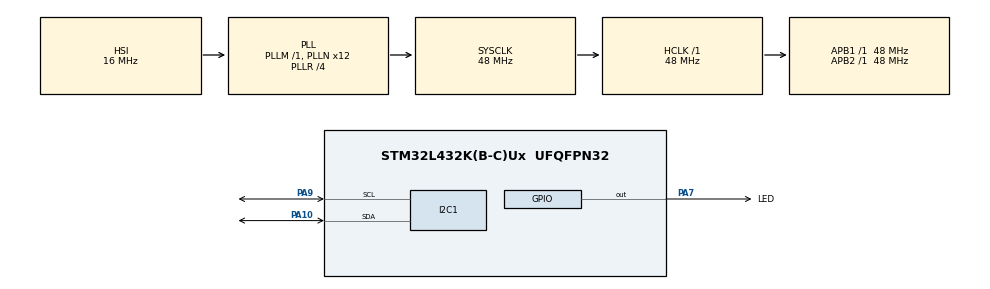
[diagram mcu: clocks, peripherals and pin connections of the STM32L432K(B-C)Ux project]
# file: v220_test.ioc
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I2C1.Timing=0x10805D88
Mcu.Family=STM32L4
Mcu.Name=STM32L432K(B-C)Ux
Mcu.Package=UFQFPN32
NVIC.PriorityGroup=NVIC_PRIORITYGROUP_4
PA10.Mode=I2C
PA10.Signal=I2C1_SDA
PA13\ (JTMS-SWDIO).Mode=Serial_Wire
PA13\ (JTMS-SWDIO).Signal=SYS_JTMS-SWDIO
PA14\ (JTCK-SWCLK).Mode=Serial_Wire
PA14\ (JTCK-SWCLK).Signal=SYS_JTCK-SWCLK
PA7.GPIO_Label=LED
PA7.Signal=GPIO_Output
PA9.Mode=I2C
PA9.Signal=I2C1_SCL
ProjectManager.HeapSize=0x400
ProjectManager.StackSize=0x800
ProjectManager.TargetToolchain=STM32CubeIDE
RCC.ADCFreq_Value=64000000
RCC.AHBFreq_Value=48000000
RCC.APB1Freq_Value=48000000
RCC.APB1TimFreq_Value=48000000
RCC.APB2Freq_Value=48000000
RCC.APB2TimFreq_Value=48000000
RCC.CortexFreq_Value=48000000
RCC.HCLKFreq_Value=48000000
RCC.HSE_VALUE=8000000
RCC.HSI48_VALUE=48000000
RCC.HSI_VALUE=16000000
RCC.LSE_VALUE=32768
RCC.MSI_VALUE=4000000
RCC.PLLN=12
RCC.PLLR=RCC_PLLR_DIV4
RCC.PLLSourceVirtual=RCC_PLLSOURCE_HSI
RCC.SYSCLKFreq_VALUE=48000000
RCC.SYSCLKSource=RCC_SYSCLKSOURCE_PLLCLK
RCC.USBFreq_Value=64000000
RCC.VCOOutputFreq_Value=192000000
board=custom

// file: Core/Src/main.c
/* USER CODE BEGIN Header */
/**
  ******************************************************************************
  * @file           : main.c
  * @brief          : Main program body
  ******************************************************************************
  * @attention
  *
  * <h2><center>&copy; Copyright (c) 2021 STMicroelectronics.
  * All rights reserved.</center></h2>
  *
  * This software component is licensed by ST under BSD 3-Clause license,
  * the "License"; You may not use this file except in compliance with the
  * License. You may obtain a copy of the License at:
  *                        opensource.org/licenses/BSD-3-Clause
  *
  ******************************************************************************
  */
/* USER CODE END Header */
#include "main.h"

/* USER CODE BEGIN Includes */
#include "stdbool.h"
#include "stdlib.h"
#include "stdio.h"
#include "inttypes.h"
#include "string.h"
#include "math.h"
#include "INA3221.h"
/* USER CODE END Includes */

/* USER CODE BEGIN PTD */

INA3221 ina;
uint32_t speed_tick_sec=0,tick=0,tick_sec=0;
float gerilim[3];

float akim[3];
int MID;

/* USER CODE END PTD */

I2C_HandleTypeDef hi2c1;

void SystemClock_Config(void);
static void MX_GPIO_Init(void);
static void MX_I2C1_Init(void);

int main(void)
{

  /* MCU Configuration--------------------------------------------------------*/

  /* Reset of all peripherals, Initializes the Flash interface and the Systick. */
  HAL_Init();

  /* Configure the system clock */
  SystemClock_Config();

  /* Initialize all configured peripherals */
  MX_GPIO_Init();
  MX_I2C1_Init();
  /* USER CODE BEGIN 2 */

  speed_tick_sec=tick=tick_sec=HAL_GetTick();
  INA3221_init(&hi2c1);
  ina.i2caddr=INA3221_ADDRESS;
  ina.shuntresistor[0]=SHUNT_10m;
  ina.shuntresistor[1]=SHUNT_10m;
  ina.shuntresistor[2]=SHUNT_10m;
  ina.enable[0]=1;
  ina.enable[1]=1;
  ina.enable[2]=1;
  ina.acdc[0]=AC;
  ina.acdc[1]=DC;
  ina.acdc[2]=DC;

  INA3221_begin(&ina);

  MID = INA3221_getManufID(&ina);
  /* USER CODE END 2 */

  /* Infinite loop */
  /* USER CODE BEGIN WHILE */
  while (1)
  {
	  tick=HAL_GetTick();

	  if(tick>=speed_tick_sec && (uint32_t)(tick-speed_tick_sec)>=3000)
	  {

		  speed_tick_sec=tick;
	  }
	  if(tick>=tick_sec && (uint32_t)(tick-tick_sec)>=500)
	  {
		  for(int i=0;i<3;i++)
		  {
		  	if(ina.enable[i]==1){

		  		if(ina.acdc[i]==AC){
		  			gerilim[i]=INA3221_getBusVoltage_V(&ina,i+1)*28.87824;
		  			gerilim[i]/=sqrt(2);
		  			gerilim[i]=(gerilim[i]==0)?0:(gerilim[i]+1);
		  		}
		  		else{
		  			gerilim[i]=INA3221_getBusVoltage_V(&ina,i+1)*28.87824;
		  			gerilim[i]=(gerilim[i]==0)?0:(gerilim[i]-1);
		  		}
		  		akim[i]=INA3221_getCurrent_mA(&ina,i+1);

		  	}
		  }
	  tick_sec=tick;
	  }

    /* USER CODE END WHILE */

  }
}

void SystemClock_Config(void)
{
  RCC_OscInitTypeDef RCC_OscInitStruct = {0};
  RCC_ClkInitTypeDef RCC_ClkInitStruct = {0};

  /** Configure the main internal regulator output voltage
  */
  if (HAL_PWREx_ControlVoltageScaling(PWR_REGULATOR_VOLTAGE_SCALE1) != HAL_OK)
  {
    Error_Handler();
  }

  /** Initializes the RCC Oscillators according to the specified parameters
  * in the RCC_OscInitTypeDef structure.
  */
  RCC_OscInitStruct.OscillatorType = RCC_OSCILLATORTYPE_HSI;
  RCC_OscInitStruct.HSIState = RCC_HSI_ON;
  RCC_OscInitStruct.HSICalibrationValue = RCC_HSICALIBRATION_DEFAULT;
  RCC_OscInitStruct.PLL.PLLState = RCC_PLL_ON;
  RCC_OscInitStruct.PLL.PLLSource = RCC_PLLSOURCE_HSI;
  RCC_OscInitStruct.PLL.PLLM = 1;
  RCC_OscInitStruct.PLL.PLLN = 12;
  RCC_OscInitStruct.PLL.PLLP = RCC_PLLP_DIV7;
  RCC_OscInitStruct.PLL.PLLQ = RCC_PLLQ_DIV2;
  RCC_OscInitStruct.PLL.PLLR = RCC_PLLR_DIV4;
  if (HAL_RCC_OscConfig(&RCC_OscInitStruct) != HAL_OK)
  {
    Error_Handler();
  }

  /** Initializes the CPU, AHB and APB buses clocks
  */
  RCC_ClkInitStruct.ClockType = RCC_CLOCKTYPE_HCLK|RCC_CLOCKTYPE_SYSCLK
                              |RCC_CLOCKTYPE_PCLK1|RCC_CLOCKTYPE_PCLK2;
  RCC_ClkInitStruct.SYSCLKSource = RCC_SYSCLKSOURCE_PLLCLK;
  RCC_ClkInitStruct.AHBCLKDivider = RCC_SYSCLK_DIV1;
  RCC_ClkInitStruct.APB1CLKDivider = RCC_HCLK_DIV1;
  RCC_ClkInitStruct.APB2CLKDivider = RCC_HCLK_DIV1;

  if (HAL_RCC_ClockConfig(&RCC_ClkInitStruct, FLASH_LATENCY_2) != HAL_OK)
  {
    Error_Handler();
  }
}

static void MX_I2C1_Init(void)
{

  hi2c1.Instance = I2C1;
  hi2c1.Init.Timing = 0x10805D88;
  hi2c1.Init.OwnAddress1 = 0;
  hi2c1.Init.AddressingMode = I2C_ADDRESSINGMODE_7BIT;
  hi2c1.Init.DualAddressMode = I2C_DUALADDRESS_DISABLE;
  hi2c1.Init.OwnAddress2 = 0;
  hi2c1.Init.OwnAddress2Masks = I2C_OA2_NOMASK;
  hi2c1.Init.GeneralCallMode = I2C_GENERALCALL_DISABLE;
  hi2c1.Init.NoStretchMode = I2C_NOSTRETCH_DISABLE;
  if (HAL_I2C_Init(&hi2c1) != HAL_OK)
  {
    Error_Handler();
  }

  /** Configure Analogue filter
  */
  if (HAL_I2CEx_ConfigAnalogFilter(&hi2c1, I2C_ANALOGFILTER_ENABLE) != HAL_OK)
  {
    Error_Handler();
  }

  /** Configure Digital filter
  */
  if (HAL_I2CEx_ConfigDigitalFilter(&hi2c1, 0) != HAL_OK)
  {
    Error_Handler();
  }

}

static void MX_GPIO_Init(void)
{
  GPIO_InitTypeDef GPIO_InitStruct = {0};

  /* GPIO Ports Clock Enable */
  __HAL_RCC_GPIOA_CLK_ENABLE();

  /*Configure GPIO pin Output Level */
  HAL_GPIO_WritePin(LED_GPIO_Port, LED_Pin, GPIO_PIN_RESET);

  /*Configure GPIO pin : LED_Pin */
  GPIO_InitStruct.Pin = LED_Pin;
  GPIO_InitStruct.Mode = GPIO_MODE_OUTPUT_PP;
  GPIO_InitStruct.Pull = GPIO_NOPULL;
  GPIO_InitStruct.Speed = GPIO_SPEED_FREQ_LOW;
  HAL_GPIO_Init(LED_GPIO_Port, &GPIO_InitStruct);

}

void Error_Handler(void)
{
  __disable_irq();
  while (1)
  {
  }
}
